AUTOSAR XML (schema 00044)
package /ComponentTypes
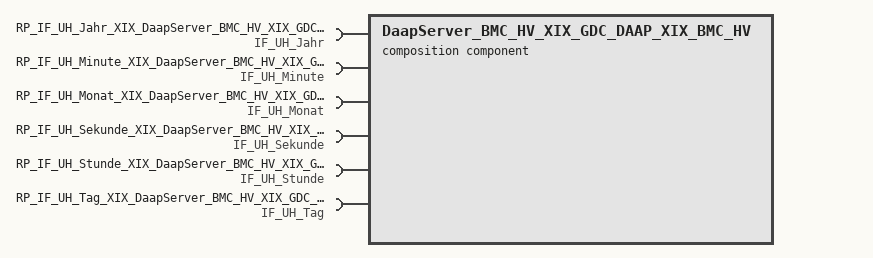
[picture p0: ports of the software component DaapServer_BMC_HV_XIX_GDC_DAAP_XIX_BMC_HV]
  composition sw component type DaapServer_BMC_HV_XIX_GDC_DAAP_XIX_BMC_HV
    6 x require port:
      RP_IF_UH_Jahr_XIX_DaapServer_BMC_HV_XIX_GDC_DAAP_XIX_BMC_HV: nonqueued-receiver-com-spec=DE_UH_Jahr, required-interface=IF_UH_Jahr
      RP_IF_UH_Minute_XIX_DaapServer_BMC_HV_XIX_GDC_DAAP_XIX_BMC_HV: nonqueued-receiver-com-spec=DE_UH_Minute, required-interface=IF_UH_Minute
      RP_IF_UH_Monat_XIX_DaapServer_BMC_HV_XIX_GDC_DAAP_XIX_BMC_HV: nonqueued-receiver-com-spec=DE_UH_Monat, required-interface=IF_UH_Monat
      RP_IF_UH_Sekunde_XIX_DaapServer_BMC_HV_XIX_GDC_DAAP_XIX_BMC_HV: nonqueued-receiver-com-spec=DE_UH_Sekunde, required-interface=IF_UH_Sekunde
      RP_IF_UH_Stunde_XIX_DaapServer_BMC_HV_XIX_GDC_DAAP_XIX_BMC_HV: nonqueued-receiver-com-spec=DE_UH_Stunde, required-interface=IF_UH_Stunde
      RP_IF_UH_Tag_XIX_DaapServer_BMC_HV_XIX_GDC_DAAP_XIX_BMC_HV: nonqueued-receiver-com-spec=DE_UH_Tag, required-interface=IF_UH_Tag
